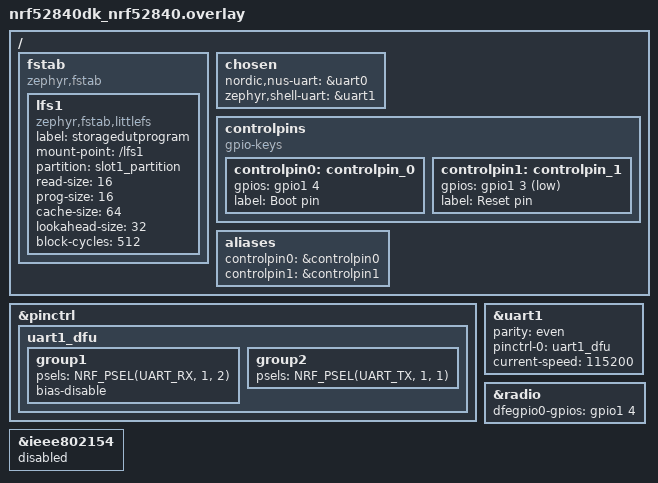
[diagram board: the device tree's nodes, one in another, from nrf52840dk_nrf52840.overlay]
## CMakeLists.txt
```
#
# Copyright (c) 2019 Peter Bigot Consulting, LLC
#
# SPDX-License-Identifier: Apache-2.0
#

cmake_minimum_required(VERSION 3.20.0)
find_package(Zephyr REQUIRED HINTS $ENV{ZEPHYR_BASE})
project(littlefs)

FILE(GLOB app_sources src/*.c)
target_sources(app PRIVATE ${app_sources})
```

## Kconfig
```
# Copyright (c) 2019 Peter Bigot Consulting, LLC
# SPDX-License-Identifier: Apache-2.0


mainmenu "littlefs sample"

config APP_WIPE_STORAGE
	bool "Option to clear the flash area before mounting"
	help
	  Use this to force an existing file system to be created.

choice
	prompt "Storage backend type used by the application"
	default APP_LITTLEFS_STORAGE_FLASH
	help
	  Specify the type of storage backend.

config APP_LITTLEFS_STORAGE_FLASH
	bool "Use flash memory backend"

config APP_LITTLEFS_STORAGE_BLK_SDMMC
	bool "Use block device (e.g. SD MMC) backend"
endchoice

menu "Nordic UART BLE GATT service sample"

config BT_NUS_THREAD_STACK_SIZE
	int "Thread stack size"
	default 1024
	help
	  Stack size used in each of the two threads

config BT_NUS_UART_BUFFER_SIZE
	int "UART payload buffer element size"
	default 40
	help
	  Size of the payload buffer in each RX and TX FIFO element

config BT_NUS_SECURITY_ENABLED
	bool "Enable security"
	default y
	select BT_SMP
	help
	  "Enable BLE security for the UART service"

config BT_NUS_UART_RX_WAIT_TIME
	int "Timeout for UART RX complete event"
	default 50
	help
	  Wait for RX complete event time in milliseconds

config BT_NUS_UART_ASYNC_ADAPTER
	bool "Enable UART async adapter"
	select SERIAL_SUPPORT_ASYNC
	help
	  Enables asynchronous adapter for UART drives that supports only
	  IRQ interface.

endmenu

source "Kconfig.zephyr"
```

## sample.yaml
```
sample:
  name: littlefs filesystem sample
tests:
  sample.filesystem.littlefs:
    build_only: true
    platform_allow: nrf52840dk_nrf52840 particle_xenon disco_l475_iot1
      mimxrt685_evk_cm33 mimxrt1060_evk mimxrt1064_evk qemu_x86 native_posix
      mimxrt1160_evk_cm7
    tags: filesystem
    integration_platforms:
      - nrf52840dk_nrf52840
sample:
  description: Bluetooth Low Energy UART service sample
  name: BLE UART service
tests:
  sample.bluetooth.peripheral_uart:
    build_only: true
    platform_allow: nrf52dk_nrf52832 nrf52833dk_nrf52833 nrf52840dk_nrf52840
      nrf5340dk_nrf5340_cpuapp nrf5340dk_nrf5340_cpuapp_ns thingy53_nrf5340_cpuapp
      thingy53_nrf5340_cpuapp_ns nrf21540dk_nrf52840
    integration_platforms:
      - nrf52dk_nrf52832
      - nrf52833dk_nrf52833
      - nrf52840dk_nrf52840
      - nrf5340dk_nrf5340_cpuapp
      - nrf5340dk_nrf5340_cpuapp_ns
      - thingy53_nrf5340_cpuapp
      - thingy53_nrf5340_cpuapp_ns
      - nrf21540dk_nrf52840
    tags: bluetooth ci_build
  sample.bluetooth.peripheral_uart_cdc:
    build_only: true
    extra_args: OVERLAY_CONFIG=prj_cdc.conf DTC_OVERLAY_FILE="usb.overlay"
    integration_platforms:
      - nrf52840dk_nrf52840
      - nrf52833dk_nrf52833
    platform_allow: nrf52840dk_nrf52840 nrf52833dk_nrf52833
    tags: bluetooth ci_build
  sample.bluetooth.peripheral_uart_minimal:
    build_only: true
    extra_args: OVERLAY_CONFIG=prj_minimal.conf
    integration_platforms:
      - nrf52dk_nrf52810
      - nrf52840dk_nrf52811
      - nrf52833dk_nrf52820
    platform_allow: nrf52dk_nrf52810 nrf52840dk_nrf52811 nrf52833dk_nrf52820
    tags: bluetooth ci_build
  sample.bluetooth.peripheral_uart_ble_rpc:
    build_only: true
    extra_configs:
      - CONFIG_BT_RPC_STACK=y
    integration_platforms:
      - nrf5340dk_nrf5340_cpuapp
    platform_allow: nrf5340dk_nrf5340_cpuapp
    tags: bluetooth ci_build
  sample.bluetooth.peripheral_uart.security_disabled:
    build_only: true
    platform_allow: nrf52dk_nrf52832 nrf52833dk_nrf52833 nrf52840dk_nrf52840
      nrf5340dk_nrf5340_cpuapp nrf5340dk_nrf5340_cpuapp_ns thingy53_nrf5340_cpuapp
      thingy53_nrf5340_cpuapp_ns nrf21540dk_nrf52840
    integration_platforms:
      - nrf52840dk_nrf52840
    tags: bluetooth ci_build
    extra_configs:
      - CONFIG_BT_NUS_SECURITY_ENABLED=n
sample:
  name: UART driver sample
tests:
  sample.drivers.uart:
    tags: serial uart
    filter: CONFIG_SERIAL and
            CONFIG_UART_INTERRUPT_DRIVEN and
            dt_chosen_enabled("zephyr,shell-uart")
            dt_chosen_enabled("zephyr,shell-uart1")
    harness: keyboard
```

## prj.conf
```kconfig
#
# Copyright (c) 2018 Nordic Semiconductor
#
# SPDX-License-Identifier: LicenseRef-Nordic-5-Clause
#

#LITTLEFS PRJCONF
# fs_dirent structures are big.
CONFIG_MAIN_STACK_SIZE=2048

# Let __ASSERT do its job
CONFIG_DEBUG=y

CONFIG_LOG=y
CONFIG_LOG_MODE_MINIMAL=y

CONFIG_FLASH=y
CONFIG_FLASH_MAP=y
CONFIG_FLASH_PAGE_LAYOUT=y

CONFIG_FILE_SYSTEM=y
CONFIG_FILE_SYSTEM_LITTLEFS=y

#BLE-UART
# Enable the UART driver
CONFIG_UART_ASYNC_API=y
#CONFIG_UART_0_ASYNC=y
CONFIG_NRFX_UARTE0=y
CONFIG_SERIAL=y

CONFIG_GPIO=y

# Make sure printk is printing to the UART console
CONFIG_CONSOLE=y
CONFIG_UART_CONSOLE=y

CONFIG_HEAP_MEM_POOL_SIZE=2048

CONFIG_BT=y
CONFIG_BT_PERIPHERAL=y
CONFIG_BT_DEVICE_NAME="FOTAproject"
CONFIG_BT_DEVICE_APPEARANCE=0
CONFIG_BT_MAX_CONN=1
CONFIG_BT_MAX_PAIRED=1

# Enable the NUS service
CONFIG_BT_NUS=y

# Enable bonding
CONFIG_BT_SETTINGS=y
CONFIG_FLASH=y
CONFIG_FLASH_PAGE_LAYOUT=y
CONFIG_FLASH_MAP=y
CONFIG_NVS=y
CONFIG_SETTINGS=y

# Enable DK LED and Buttons library
CONFIG_DK_LIBRARY=y

# This example requires more workqueue stack
CONFIG_SYSTEM_WORKQUEUE_STACK_SIZE=2048

# Config logger
CONFIG_LOG=y
CONFIG_USE_SEGGER_RTT=y
CONFIG_LOG_BACKEND_RTT=y
CONFIG_LOG_BACKEND_UART=n
CONFIG_LOG_PRINTK=n

CONFIG_SERIAL=y
CONFIG_BT_NUS_UART_BUFFER_SIZE=502
CONFIG_NRF_CC3XX_PLATFORM=y
CONFIG_ONOFF=y
CONFIG_FLASH_SIZE=1024
CONFIG_PM_PARTITION_SIZE_PROVISION=0x1000
CONFIG_SRAM_SIZE=256
CONFIG_SRAM_BASE_ADDRESS=0x20000000
CONFIG_CONSOLE_INIT_PRIORITY=60
CONFIG_DEBUG_THREAD_INFO=y
CONFIG_XOSHIRO_RANDOM_GENERATOR=y

CONFIG_BT_USER_PHY_UPDATE=y
CONFIG_BT_GATT_CLIENT=y

CONFIG_BT_USER_DATA_LEN_UPDATE=y
CONFIG_BT_CTLR_DATA_LENGTH_MAX=251
CONFIG_BT_BUF_ACL_RX_SIZE=251
CONFIG_BT_BUF_ACL_TX_SIZE=251
CONFIG_BT_L2CAP_TX_MTU=247
```

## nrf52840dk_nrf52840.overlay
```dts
/*
 * Copyright (c) 2019 Peter Bigot Consulting, LLC
 *
 * SPDX-License-Identifier: Apache-2.0
 */
 
 //Code to change partitions size
 /*/delete-node/ &scratch_partition;
 /delete-node/ &slot0_partition;*/

 &pinctrl {
    uart1_dfu: uart1_dfu {
		group1 {
			psels = <NRF_PSEL(UART_RX, 1, 2)>;
			bias-disable;
		};
		group2 {
			psels = <NRF_PSEL(UART_TX, 1, 1)>;
		};
	};
};

&uart1 {
	status = "okay";
	parity = "even";
	pinctrl-0 = <&uart1_dfu>;
	current-speed = < 115200>;
};



/ {
	fstab {
		compatible = "zephyr,fstab";
		lfs1: lfs1 {
			label = "storagedutprogram";
			compatible = "zephyr,fstab,littlefs";
			mount-point = "/lfs1";
			partition = <&slot1_partition>; // storage place changed to have enough space
			//automount;
			read-size = <16>;
			prog-size = <16>;
			cache-size = <64>;
			lookahead-size = <32>;
			block-cycles = <512>; 
		};
	};
};

/ {
	chosen {
		nordic,nus-uart = &uart0;
		zephyr,shell-uart = &uart1;
	};
};
/{
	controlpins {
        compatible = "gpio-keys";
        controlpin0: controlpin_0 {
            gpios = <&gpio1 4 GPIO_ACTIVE_HIGH>;
            label = "Boot pin";
        };
		controlpin1: controlpin_1 {
            gpios = <&gpio1 3 GPIO_ACTIVE_LOW>;
            label = "Reset pin";
        };
    };
    aliases {
        controlpin0 = &controlpin0;
		controlpin1 = &controlpin1;
    };
};



&radio {
    dfegpio0-gpios = <&gpio1 4 0>;
};

&ieee802154 {
    status = "disabled";
};
```

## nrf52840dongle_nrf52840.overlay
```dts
/*
 * Copyright (c) 2019 Peter Bigot Consulting, LLC
 *
 * SPDX-License-Identifier: Apache-2.0
 */
 
 //Code to change partitions size
 /*/delete-node/ &scratch_partition;
 /delete-node/ &slot0_partition;*/
 /{



	chosen {
		nordic,nus-uart = &uart0;
		zephyr,shell-uart = &uart1;
	};


};

 &pinctrl {
    uart1_dfu: uart1_dfu {
		group1 {
			psels = <NRF_PSEL(UART_RX, 0, 15)>,
		   <NRF_PSEL(UART_CTS, 0, 1)>,
		   <NRF_PSEL(UART_RTS, 0, 0)>;
			//bias-disable;
		};
		group2 {
			psels = <NRF_PSEL(UART_TX, 0, 13)>;
			//bias-disable;
		};
	};

	uart1_default: uart1_default {
		group1 {
			psels = <NRF_PSEL(UART_TX, 0, 15)>, <NRF_PSEL(UART_RX, 0, 13)>;
		};
	};
};




/ {
	fstab {
		compatible = "zephyr,fstab";
		lfs1: lfs1 {
			label = "storagedutprogram";
			compatible = "zephyr,fstab,littlefs";
			mount-point = "/lfs1";
			partition = <&slot1_partition>; // storage place changed to have enough space
			//automount;
			read-size = <16>;
			prog-size = <16>;
			cache-size = <64>;
			lookahead-size = <32>;
			block-cycles = <512>; 
		};
	};
};


&uart1 {
	status = "okay";
	pinctrl-0 = <&uart1_default>;
	current-speed = < 9600 >;
	parity = "even";
	pinctrl-names = "default";
};
```

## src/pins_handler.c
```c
#include "pins_handler.h"


void pins_init(){
	if (!device_is_ready(bootpin.port)) {
		return;
	}
	gpio_pin_configure_dt(&bootpin, GPIO_OUTPUT_ACTIVE);


	if (!device_is_ready(resetpin.port)) {
		return;
	}
	gpio_pin_configure_dt(&resetpin, GPIO_OUTPUT_INACTIVE);
	
	reset_stm();
}

void boot_activation(bool onoff){
	if(onoff){
		gpio_pin_configure_dt(&bootpin, GPIO_OUTPUT_ACTIVE);
	}
	else{
		gpio_pin_configure_dt(&bootpin, GPIO_OUTPUT_INACTIVE);
	}
	
}

void reset_stm(){
	gpio_pin_configure_dt(&resetpin, GPIO_OUTPUT_INACTIVE);
	k_msleep(100);
	gpio_pin_configure_dt(&resetpin, GPIO_OUTPUT_ACTIVE);

	k_msleep(100);
	gpio_pin_configure_dt(&resetpin, GPIO_OUTPUT_INACTIVE);
}
```

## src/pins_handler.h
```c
#ifndef PINS_HANDLER_H
#define PINS_HANDLER_H

#include <zephyr/kernel.h>
#include <zephyr/device.h>
#include <zephyr/drivers/gpio.h>
#include <zephyr/logging/log.h>


/*PINS BOOT AND RESET*/
#define BOOT_NODE DT_ALIAS(controlpin0)
#define RESET_NODE DT_ALIAS(controlpin1)

static const struct gpio_dt_spec bootpin = GPIO_DT_SPEC_GET(BOOT_NODE, gpios);
static const struct gpio_dt_spec resetpin = GPIO_DT_SPEC_GET(RESET_NODE, gpios);


void pins_init();
void boot_activation(bool onoff);
void reset_stm();
#endif
```
